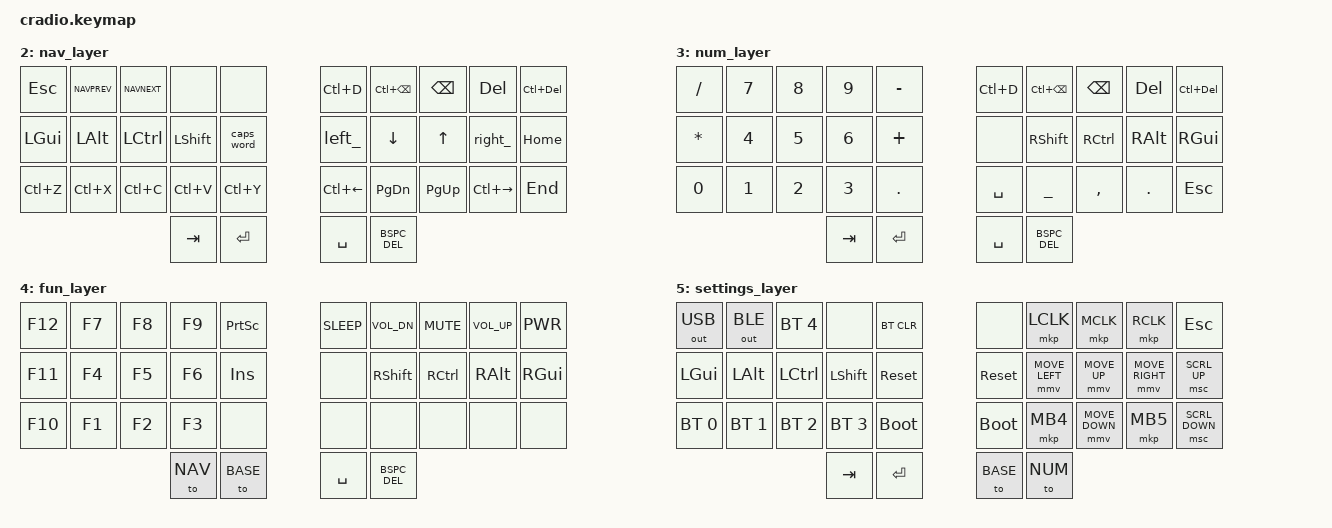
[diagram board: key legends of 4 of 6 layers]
/*
 * Copyright (c) 2020 The ZMK Contributors
 *
 * SPDX-License-Identifier: MIT
 */

#include <behaviors.dtsi>
#include <dt-bindings/zmk/keys.h>
#include <dt-bindings/zmk/bt.h>
#include <dt-bindings/zmk/outputs.h>

// https://zmk.dev/docs/keymaps/behaviors/mouse-emulation
#define ZMK_POINTING_DEFAULT_MOVE_VAL 600
#define ZMK_POINTING_SCRL_MOVE_VAL 10
#include <dt-bindings/zmk/pointing.h>


// Layer definitions
#define BASE 0      // Base alphanumeric layer
#define SYM 1       // A layer for all the symbol keys
#define NAV 2       // Navigation keys on the right hand
#define NUM 3       // Numeric keypad on left hand
#define FUN 4       // Function keys on left and media on right hand
#define SETTINGS 5  // Settings layer (mouse nav keys on right hand)

// Home row modifiers: see https://github.com/urob/zmk-config#timeless-homerow-mods
#define HL(k1,k2,k3,k4) &hml LGUI  k1 &hml LALT  k2 &hml LCTRL k3 &hml LSHFT k4
#define HR(k1,k2,k3,k4) &hmr RSHFT k1 &hmr RCTRL k2 &hmr RALT  k3 &hmr RGUI  k4

// Key positions on left and right keyboard splits
#define KEYS_L 0 1 2 3 4 10 11 12 13 14 20 21 22 23 24
#define KEYS_R 5 6 7 8 9 15 16 17 18 19 25 26 27 28 29
#define THUMBS 30 31 32 33

&lt {  // layer-tap config
    flavor = "balanced";
    tapping-term-ms = <200>;
    quick-tap-ms = <225>;
};
&mt {  // mod-tap config
    flavor = "balanced";
    tapping-term-ms = <200>;
    quick-tap-ms = <225>;
};

/ {
    behaviors {
        // See https://github.com/urob/zmk-config#timeless-homerow-mods
        hml: hml {  // Left side Home Row Modifiers
            compatible = "zmk,behavior-hold-tap";
            #binding-cells = <2>;
            bindings = <&kp>, <&kp>;
            flavor = "balanced";                // Force a `hold` if another key is pressed while held
            hold-trigger-key-positions = <KEYS_R THUMBS>; // Immediate hold if key is on the other side
            require-prior-idle-ms = <150>;      // Force immediate tap if <150ms since last tap (avoids delay)
            hold-trigger-on-release;            // Wait in case another modifier is pressed
            tapping-term-ms = <280>;            // Force hold for both sides after holding for 280ms
            quick-tap-ms = <200>;               // Produce repeating key tap if double tapped within 200ms
        };
        hmr: hmr {  // Right side Home Row Modifiers
            compatible = "zmk,behavior-hold-tap";
            #binding-cells = <2>;
            bindings = <&kp>, <&kp>;
            flavor = "balanced";
            hold-trigger-key-positions = <KEYS_L THUMBS>;
            require-prior-idle-ms = <150>;
            hold-trigger-on-release;
            tapping-term-ms = <280>;
            quick-tap-ms = <200>;
        };
        BSPC_DEL: BSPC_DEL { // tap: BSPC, Shift-tap: DEL
            compatible = "zmk,behavior-mod-morph";
            #binding-cells = <0>;
            bindings = <&kp BSPC>, <&kp DEL>;
            mods = <(MOD_LSFT|MOD_RSFT)>;
        };
        NUM_BSPC_DEL: NUM_BSPC_DEL { // hold: NUM layer, tap: BSPC, Shift-tap: DEL
            compatible = "zmk,behavior-mod-morph";
            #binding-cells = <0>;
            bindings = <&lt NUM BSPC>, <&kp DEL>;
            mods = <(MOD_LSFT|MOD_RSFT)>;
        };
        SYM_ENTER_ESC: SYM_ENTER_ESC { // hold: SYM layer, tap: ENTER, Shift-tap: ESC
            compatible = "zmk,behavior-mod-morph";
            #binding-cells = <0>;
            bindings = <&lt SYM ENTER>, <&kp ESC>;
            mods = <(MOD_RSFT)>;
        };
        right_: right_ { // ALT+RIGHTARROW is indent (ctrl-])
            compatible = "zmk,behavior-mod-morph";
            #binding-cells = <0>;
            bindings = <&kp RIGHT>, <&kp LC(RBKT)>;
            mods = <(MOD_LALT)>;
        };
        left_: left_ { // ALT+LEFTARROW is dedent (ctrl-[)
            compatible = "zmk,behavior-mod-morph";
            #binding-cells = <0>;
            bindings = <&kp LEFT>, <&kp LC(LBKT)>;
            mods = <(MOD_LALT)>;
        };
    };
    combos {
        compatible = "zmk,combos";
        // Both left keys - SETTINGS layer
        combo_left_thumbs {
            bindings = <&mo SETTINGS>;
            key-positions = <30 31>;
            timeout-ms = <500>;
        };
        // Both right keys - FUN layer
        combo_right_thumbs {
            bindings = <&mo FUN>;
            key-positions = <32 33>;
            timeout-ms = <500>;
        };
        // Both outer thumb keys - return to BASE layer
        combo_outer_thumbs {
            bindings = <&to BASE>;
            key-positions = <30 33>;
            timeout-ms = <500>;
        };
        // LEFT, DOWN, UP, RIGHT combo keys on left hand bottom row
        combo_left_1 {
            bindings = <&kp LEFT>;
            key-positions = <20 21>;
            timeout-ms = <150>;
        };
        combo_down_1 {
            bindings = <&kp DOWN>;
            key-positions = <21 22>;
            timeout-ms = <150>;
        };
        combo_up_1 {
            bindings = <&kp UP>;
            key-positions = <22 23>;
            timeout-ms = <150>;
        };
        combo_right_1 {
            bindings = <&kp RIGHT>;
            key-positions = <23 24>;
            timeout-ms = <150>;
        };
        // LEFT, DOWN, UP, RIGHT combo keys on right hand bottom row
        combo_left_2 {
            bindings = <&kp LEFT>;
            key-positions = <25 26>;
            timeout-ms = <150>;
        };
        combo_down_2 {
            bindings = <&kp DOWN>;
            key-positions = <26 27>;
            timeout-ms = <150>;
        };
        combo_up_2 {
            bindings = <&kp UP>;
            key-positions = <27 28>;
            timeout-ms = <150>;
        };
        combo_right_2 {
            bindings = <&kp RIGHT>;
            key-positions = <28 29>;
            timeout-ms = <150>;
        };
    };

    keymap {
        compatible = "zmk,keymap";

        // For going to prev/next navigation position in vscode and other apps.
        #define NAVPREV LA(LC(MINUS))
        #define NAVNEXT LS(LC(MINUS))

        default_layer { // Base alpha layer
            bindings = <
            &kp Q       &kp W       &kp E       &kp R       &kp T           &kp Y       &kp U       &kp I       &kp O       &kp P
            HL( A,          S,          D,          F)      &kp G           &kp H        HR(J,          K,          L,          SEMI)
            &kp Z       &kp X       &kp C       &kp V       &kp B           &kp N       &kp M       &kp COMMA   &kp DOT     &kp FSLH
                                        &lt NAV TAB &SYM_ENTER_ESC          &mt RSHIFT SPACE &NUM_BSPC_DEL
            >;
        };
        sym_layer { // Symbols
            bindings = <
            &kp EXCL    &kp AT      &kp HASH    &kp DLLR    &kp PRCNT       &kp CARET   &kp AMPS    &kp ASTRK   &kp LPAR    &kp RPAR
            HL( GRAVE,      LT,         QMARK,      SQT)    &kp SEMI        &kp PIPE    HR( MINUS,      PLUS,       LBKT,       RBKT)
            &kp TILDE   &kp GT      &kp EXCL    &kp DQT     &kp COLON       &kp BSLH    &kp UNDER   &kp EQUAL   &kp LBRC    &kp RBRC
                                                &kp TAB     &kp ENTER       &kp SPACE   &BSPC_DEL
            >;
        };
        nav_layer { // Navigation RIGHT_HJKL
            bindings = <
            &kp ESC     &kp NAVPREV &kp NAVNEXT &none       &none           &kp LC(D)   &kp LC(BSPC)&kp BSPC    &kp DEL     &kp LC(DEL)
            &kp LGUI    &kp LALT    &kp LCTRL   &kp LSHFT   &caps_word      &left_      &kp DOWN    &kp UP      &right_     &kp HOME
            &kp LC(Z)   &kp LC(X)   &kp LC(C)   &kp LC(V)   &kp LC(Y)       &kp LC(LEFT)&kp PG_DN   &kp PG_UP   &kp LC(RIGHT)&kp END
                                                &kp TAB     &kp ENTER       &kp SPACE   &BSPC_DEL
            >;
        };
        num_layer { // Numbers
            bindings = <
            &kp FSLH    &kp N7      &kp N8      &kp N9      &kp MINUS       &kp LC(D)   &kp LC(BSPC)&kp BSPC    &kp DEL     &kp LC(DEL)
            &kp ASTRK   &kp N4      &kp N5      &kp N6      &kp PLUS        &none       &kp RSHFT   &kp RCTRL   &kp RALT    &kp RGUI
            &kp N0      &kp N1      &kp N2      &kp N3      &kp DOT         &kp SPACE   &kp UNDER   &kp COMMA   &kp DOT     &kp ESC
                                                &kp TAB     &kp ENTER       &kp SPACE   &BSPC_DEL
            >;
        };
        fun_layer { // Function keys and media
            bindings = <
            &kp F12     &kp F7      &kp F8      &kp F9      &kp PSCRN       &kp C_SLEEP &kp C_VOL_DN &kp C_MUTE  &kp C_VOL_UP &kp C_PWR
            &kp F11     &kp F4      &kp F5      &kp F6      &kp INSERT      &none       &kp RSHFT   &kp RCTRL   &kp RALT    &kp RGUI
            &kp F10     &kp F1      &kp F2      &kp F3      &none           &none       &none       &none       &none       &none
                                                &to NAV     &to BASE        &kp SPACE   &BSPC_DEL
            >;
        };
        settings_layer { // Used to change the keyboard's settings and mouse control.
            bindings = <
            &out OUT_USB &out OUT_BLE &bt BT_SEL 4 &none        &bt BT_CLR      &none       &mkp LCLK      &mkp MCLK      &mkp RCLK       &kp ESC
            &kp LGUI     &kp LALT     &kp LCTRL    &kp LSHFT    &sys_reset      &sys_reset  &mmv MOVE_LEFT &mmv MOVE_UP   &mmv MOVE_RIGHT &msc SCRL_UP
            &bt BT_SEL 0 &bt BT_SEL 1 &bt BT_SEL 2 &bt BT_SEL 3 &bootloader     &bootloader &mkp MB4       &mmv MOVE_DOWN &mkp MB5        &msc SCRL_DOWN
                                                   &kp TAB      &kp ENTER       &to BASE    &to NUM
            >;
        };
    };
};
